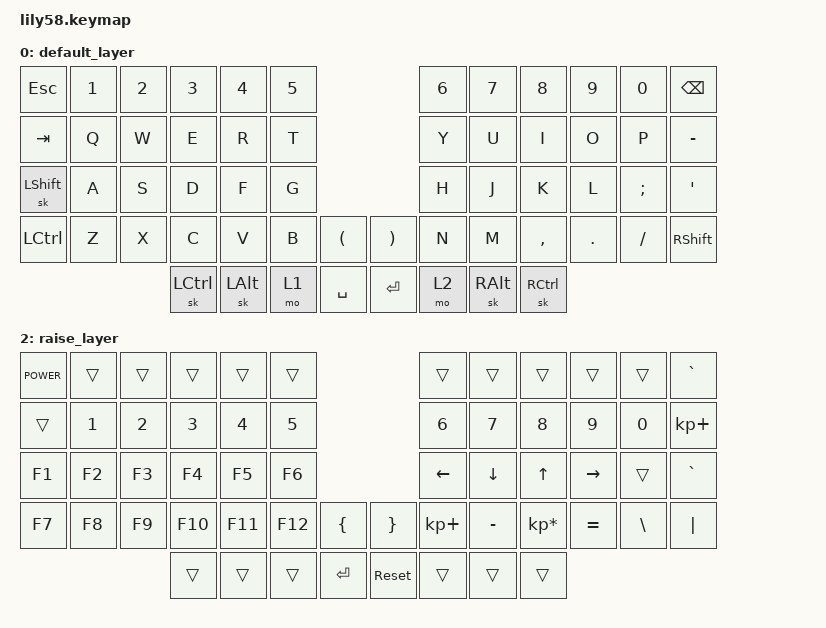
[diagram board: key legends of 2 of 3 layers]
/*
 * Copyright (c) 2020 The ZMK Contributors
 *
 * SPDX-License-Identifier: MIT
 */

#include <behaviors.dtsi>
#include <dt-bindings/zmk/keys.h>
#include <dt-bindings/zmk/bt.h>
#include <dt-bindings/zmk/ext_power.h>

&caps_word {
    continue-list = <UNDERSCORE MINUS BACKSPACE DELETE>;
};

&sl {
    release-after-ms = <250>;
};

&sk {
    release-after-ms = <250>;
};

/ {
    keymap {
        compatible = "zmk,keymap";

        default_layer {
            bindings = <
&kp ESC    &kp N1 &kp N2 &kp N3    &kp N4   &kp N5                      &kp N6 &kp N7   &kp N8    &kp N9  &kp N0   &kp BSPC
&kp TAB    &kp Q  &kp W  &kp E     &kp R    &kp T                       &kp Y  &kp U    &kp I     &kp O   &kp P    &kp MINUS
&sk LSHFT  &kp A  &kp S  &kp D     &kp F    &kp G                       &kp H  &kp J    &kp K     &kp L   &kp SEMI &kp SQT
&kp LCTRL  &kp Z  &kp X  &kp C     &kp V    &kp B  &kp LPAR   &kp RPAR  &kp N  &kp M    &kp COMMA &kp DOT &kp FSLH &kp RSHFT
                         &sk LCTRL &sk LALT &mo 1  &kp SPACE  &kp RET   &mo 2  &sk RALT &sk RCTRL
            >;

            sensor-bindings = <&inc_dec_kp C_VOL_UP C_VOL_DN>;
        };

        lower_layer {
            bindings = <
&bt BT_CLR &bt BT_SEL 0     &bt BT_SEL 1      &bt BT_SEL 2      &bt BT_SEL 3 &bt BT_SEL 4                  &trans    &trans    &trans          &trans    &trans    &kp DEL
&trans     &kp F2           &kp F3            &kp F4            &kp F5       &kp F6                        &kp F7    &kp F8    &kp F9          &kp F10   &kp F11   &kp PSCRN
&caps_word &kp EXCL         &kp AT            &kp HASH          &kp DOLLAR   &kp PRCNT                     &kp CARET &kp AMPS  &kp KP_MULTIPLY &kp LPAR  &kp RPAR  &kp TILDE
&kp LGUI   &ext_power EP_ON &ext_power EP_OFF &ext_power EP_TOG &trans       &trans    &kp LBKT  &kp RBKT  &trans    &kp MINUS &kp KP_PLUS     &kp LBRC  &kp RBRC  &kp PIPE
                                              &sys_reset        &trans    &kp RET   &kp RET   &trans    &trans    &trans
            >;

            sensor-bindings = <&inc_dec_kp C_VOL_UP C_VOL_DN>;
        };

        raise_layer {
            bindings = <
&kp K_POWER &trans &trans &trans  &trans  &trans                        &trans      &trans    &trans          &trans     &trans    &kp GRAVE
&trans     &kp N1 &kp N2 &kp N3  &kp N4  &kp N5                         &kp N6      &kp N7    &kp N8          &kp N9     &kp N0    &kp KP_PLUS
&kp F1     &kp F2 &kp F3 &kp F4  &kp F5  &kp F6                         &kp LEFT    &kp DOWN  &kp UP          &kp RIGHT  &trans    &kp GRAVE
&kp F7     &kp F8 &kp F9 &kp F10 &kp F11 &kp F12   &kp LBRC  &kp RBRC   &kp KP_PLUS &kp MINUS &kp KP_MULTIPLY &kp EQUAL  &kp BSLH  &kp PIPE 
                         &trans  &trans  &trans    &kp RET   &sys_reset &trans      &trans    &trans
            >;

            sensor-bindings = <&inc_dec_kp C_VOL_UP C_VOL_DN>;
        };
    };
};
